AUTOSAR XML (schema 00048)
package /HuaweiMDC/FunctionalSoftware/CameraLidarDetectionApplication/Execution
  executable CameraLidarDetectionExecutable
    root sw component prototype CameraLidarDetectionRootSwComponent: application-type=CameraLidarDetectionApplicationSwComponent
package /HuaweiMDC/FunctionalSoftware/CameraLidarDetectionApplication/SwComponent
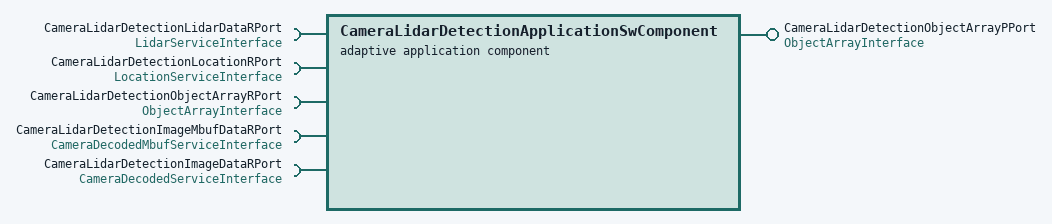
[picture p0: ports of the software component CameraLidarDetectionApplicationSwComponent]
  adaptive application sw component type CameraLidarDetectionApplicationSwComponent
    require port CameraLidarDetectionLidarDataRPort: required-interface=LidarServiceInterface
    require port CameraLidarDetectionLocationRPort: required-interface=LocationServiceInterface
    provide port CameraLidarDetectionObjectArrayPPort: provided-interface=ObjectArrayInterface
    require port CameraLidarDetectionObjectArrayRPort: required-interface=ObjectArrayInterface
    require port CameraLidarDetectionImageMbufDataRPort: required-interface=CameraDecodedMbufServiceInterface
    require port CameraLidarDetectionImageDataRPort: required-interface=CameraDecodedServiceInterface
